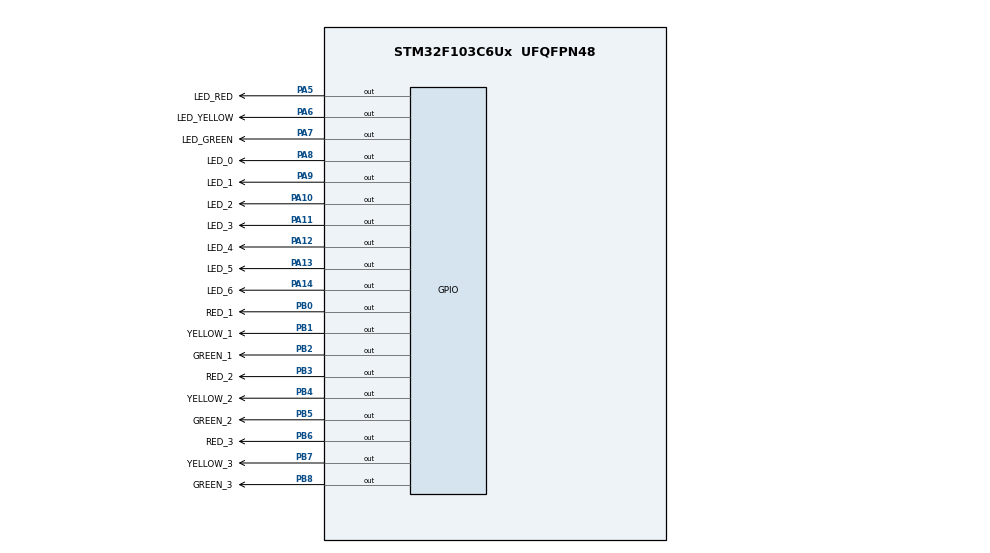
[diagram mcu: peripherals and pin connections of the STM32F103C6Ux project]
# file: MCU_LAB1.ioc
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Mcu.Family=STM32F1
Mcu.Name=STM32F103C6Ux
Mcu.Package=UFQFPN48
NVIC.PriorityGroup=NVIC_PRIORITYGROUP_4
PA10.GPIO_Label=LED_2
PA10.Signal=GPIO_Output
PA11.GPIO_Label=LED_3
PA11.Signal=GPIO_Output
PA12.GPIO_Label=LED_4
PA12.Signal=GPIO_Output
PA13.GPIO_Label=LED_5
PA13.Signal=GPIO_Output
PA14.GPIO_Label=LED_6
PA14.Signal=GPIO_Output
PA5.GPIO_Label=LED_RED
PA5.Signal=GPIO_Output
PA6.GPIO_Label=LED_YELLOW
PA6.Signal=GPIO_Output
PA7.GPIO_Label=LED_GREEN
PA7.Signal=GPIO_Output
PA8.GPIO_Label=LED_0
PA8.Signal=GPIO_Output
PA9.GPIO_Label=LED_1
PA9.Signal=GPIO_Output
PB0.GPIO_Label=RED_1
PB0.Signal=GPIO_Output
PB1.GPIO_Label=YELLOW_1
PB1.Signal=GPIO_Output
PB2.GPIO_Label=GREEN_1
PB2.Signal=GPIO_Output
PB3.GPIO_Label=RED_2
PB3.Signal=GPIO_Output
PB4.GPIO_Label=YELLOW_2
PB4.Signal=GPIO_Output
PB5.GPIO_Label=GREEN_2
PB5.Signal=GPIO_Output
PB6.GPIO_Label=RED_3
PB6.Signal=GPIO_Output
PB7.GPIO_Label=YELLOW_3
PB7.Signal=GPIO_Output
PB8.GPIO_Label=GREEN_3
PB8.Signal=GPIO_Output
ProjectManager.HeapSize=0x200
ProjectManager.StackSize=0x400
ProjectManager.TargetToolchain=STM32CubeIDE
RCC.APB1Freq_Value=8000000
RCC.APB2Freq_Value=8000000
VP_SYS_VS_ND.Mode=No_Debug
board=custom

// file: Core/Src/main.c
/* USER CODE BEGIN Header */
/**
  ******************************************************************************
  * @file           : main.c
  * @brief          : Main program body
  ******************************************************************************
  * @attention
  *
  * <h2><center>&copy; Copyright (c) 2024 STMicroelectronics.
  * All rights reserved.</center></h2>
  *
  * This software component is licensed by ST under BSD 3-Clause license,
  * the "License"; You may not use this file except in compliance with the
  * License. You may obtain a copy of the License at:
  *                        opensource.org/licenses/BSD-3-Clause
  *
  ******************************************************************************
  */
/* USER CODE END Header */
#include "main.h"
/* USER CODE BEGIN Includes */
#include "Ex1.h"
#include "Ex2.h"
#include "Ex3.h"
#include "Ex4.h"
#include "Ex5.h"
#include "Ex6.h"
#include "Ex7.h"
#include "Ex8.h"
#include "Ex9.h"
#include "Ex10.h"
/* USER CODE END Includes */

void SystemClock_Config(void);
static void MX_GPIO_Init(void);

int main(void)
{

  /* MCU Configuration--------------------------------------------------------*/

  /* Reset of all peripherals, Initializes the Flash interface and the Systick. */
  HAL_Init();

  /* USER CODE BEGIN Init */
  int count = 0;
  /* USER CODE END Init */

  /* Configure the system clock */
  SystemClock_Config();

  /* Initialize all configured peripherals */
  MX_GPIO_Init();
  /* USER CODE BEGIN 2 */
  init_Exercise3();
  /* USER CODE END 2 */

  /* Infinite loop */
  /* USER CODE BEGIN WHILE */
  while (1)
  {
	  run_Exercise5(count++);
	  HAL_Delay(1000);
    /* USER CODE END WHILE */

  }
}

void SystemClock_Config(void)
{
  RCC_OscInitTypeDef RCC_OscInitStruct = {0};
  RCC_ClkInitTypeDef RCC_ClkInitStruct = {0};

  /** Initializes the RCC Oscillators according to the specified parameters
  * in the RCC_OscInitTypeDef structure.
  */
  RCC_OscInitStruct.OscillatorType = RCC_OSCILLATORTYPE_HSI;
  RCC_OscInitStruct.HSIState = RCC_HSI_ON;
  RCC_OscInitStruct.HSICalibrationValue = RCC_HSICALIBRATION_DEFAULT;
  RCC_OscInitStruct.PLL.PLLState = RCC_PLL_NONE;
  if (HAL_RCC_OscConfig(&RCC_OscInitStruct) != HAL_OK)
  {
    Error_Handler();
  }
  /** Initializes the CPU, AHB and APB buses clocks
  */
  RCC_ClkInitStruct.ClockType = RCC_CLOCKTYPE_HCLK|RCC_CLOCKTYPE_SYSCLK
                              |RCC_CLOCKTYPE_PCLK1|RCC_CLOCKTYPE_PCLK2;
  RCC_ClkInitStruct.SYSCLKSource = RCC_SYSCLKSOURCE_HSI;
  RCC_ClkInitStruct.AHBCLKDivider = RCC_SYSCLK_DIV1;
  RCC_ClkInitStruct.APB1CLKDivider = RCC_HCLK_DIV1;
  RCC_ClkInitStruct.APB2CLKDivider = RCC_HCLK_DIV1;

  if (HAL_RCC_ClockConfig(&RCC_ClkInitStruct, FLASH_LATENCY_0) != HAL_OK)
  {
    Error_Handler();
  }
}

static void MX_GPIO_Init(void)
{
  GPIO_InitTypeDef GPIO_InitStruct = {0};

  /* GPIO Ports Clock Enable */
  __HAL_RCC_GPIOA_CLK_ENABLE();
  __HAL_RCC_GPIOB_CLK_ENABLE();

  /*Configure GPIO pin Output Level */
  HAL_GPIO_WritePin(GPIOA, LED_RED_Pin|LED_YELLOW_Pin|LED_GREEN_Pin|LED_0_Pin
                          |LED_1_Pin|LED_2_Pin|LED_3_Pin|LED_4_Pin
                          |LED_5_Pin|LED_6_Pin, GPIO_PIN_RESET);

  /*Configure GPIO pin Output Level */
  HAL_GPIO_WritePin(GPIOB, RED_1_Pin|YELLOW_1_Pin|GREEN_1_Pin|RED_2_Pin
                          |YELLOW_2_Pin|GREEN_2_Pin|RED_3_Pin|YELLOW_3_Pin
                          |GREEN_3_Pin, GPIO_PIN_RESET);

  /*Configure GPIO pins : LED_RED_Pin LED_YELLOW_Pin LED_GREEN_Pin LED_0_Pin
                           LED_1_Pin LED_2_Pin LED_3_Pin LED_4_Pin
                           LED_5_Pin LED_6_Pin */
  GPIO_InitStruct.Pin = LED_RED_Pin|LED_YELLOW_Pin|LED_GREEN_Pin|LED_0_Pin
                          |LED_1_Pin|LED_2_Pin|LED_3_Pin|LED_4_Pin
                          |LED_5_Pin|LED_6_Pin;
  GPIO_InitStruct.Mode = GPIO_MODE_OUTPUT_PP;
  GPIO_InitStruct.Pull = GPIO_NOPULL;
  GPIO_InitStruct.Speed = GPIO_SPEED_FREQ_LOW;
  HAL_GPIO_Init(GPIOA, &GPIO_InitStruct);

  /*Configure GPIO pins : RED_1_Pin YELLOW_1_Pin GREEN_1_Pin RED_2_Pin
                           YELLOW_2_Pin GREEN_2_Pin RED_3_Pin YELLOW_3_Pin
                           GREEN_3_Pin */
  GPIO_InitStruct.Pin = RED_1_Pin|YELLOW_1_Pin|GREEN_1_Pin|RED_2_Pin
                          |YELLOW_2_Pin|GREEN_2_Pin|RED_3_Pin|YELLOW_3_Pin
                          |GREEN_3_Pin;
  GPIO_InitStruct.Mode = GPIO_MODE_OUTPUT_PP;
  GPIO_InitStruct.Pull = GPIO_NOPULL;
  GPIO_InitStruct.Speed = GPIO_SPEED_FREQ_LOW;
  HAL_GPIO_Init(GPIOB, &GPIO_InitStruct);

}

void Error_Handler(void)
{
  __disable_irq();
  while (1)
  {
  }
}

/************************ (C) COPYRIGHT STMicroelectronics *****END OF FILE****/
